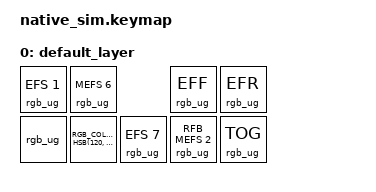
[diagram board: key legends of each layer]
/*
 * Copyright (c) 2026 The ZMK Contributors
 *
 * SPDX-License-Identifier: MIT
 */

#include <dt-bindings/zmk/keys.h>
#include <behaviors.dtsi>
#include <dt-bindings/zmk/kscan_mock.h>
#include <dt-bindings/zmk/rgb.h>
#include <zephyr/dt-bindings/led/led.h>

/ {
    chosen {
        zmk,underglow = &led_strip;
    };

    // A real led_strip device on native_sim: bit-banged over the emulated GPIO controller.
    led_strip: led_strip {
        compatible = "ti,tlc59731";
        gpios = <&gpio0 2 GPIO_ACTIVE_HIGH>;
        chain-length = <3>;
        color-mapping = <LED_COLOR_ID_RED LED_COLOR_ID_GREEN LED_COLOR_ID_BLUE>;
    };

    keymap {
        compatible = "zmk,keymap";

        default_layer {
            bindings = <
                &rgb_ug RGB_EFS 1                  &rgb_ug RGB_MEFS_CMD 6 &rgb_ug RGB_EFF  &rgb_ug RGB_EFR
                &rgb_ug RGB_COLOR_HSB(120, 50, 40) &rgb_ug RGB_EFS 7      &rgb_ug RFB_MEFS 2 &rgb_ug RGB_TOG
            >;
        };
    };
};

&kscan {
    rows = <2>;
    columns = <4>;
    events = <
        /* RGB_EFS 1 */
        ZMK_MOCK_PRESS(0,0,10) ZMK_MOCK_RELEASE(0,0,10)
        /* RGB_MEFS_CMD 6, held over several ticks */
        ZMK_MOCK_PRESS(0,1,200) ZMK_MOCK_RELEASE(0,1,10)
        /* RGB_EFF, RGB_EFR */
        ZMK_MOCK_PRESS(0,2,10) ZMK_MOCK_RELEASE(0,2,10)
        ZMK_MOCK_PRESS(0,3,10) ZMK_MOCK_RELEASE(0,3,10)
        /* RGB_COLOR_HSB (command 15), RGB_EFS 7 (out of range, rejected) */
        ZMK_MOCK_PRESS(1,0,10) ZMK_MOCK_RELEASE(1,0,10)
        ZMK_MOCK_PRESS(1,1,10) ZMK_MOCK_RELEASE(1,1,10)
        /* RFB_MEFS 2 (Kinesis alias) */
        ZMK_MOCK_PRESS(1,2,100) ZMK_MOCK_RELEASE(1,2,10)
        /* RGB_TOG */
        ZMK_MOCK_PRESS(1,3,10) ZMK_MOCK_RELEASE(1,3,10)
    >;
};
